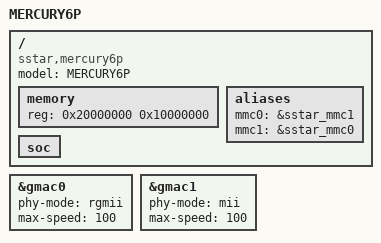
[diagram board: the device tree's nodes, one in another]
/*
* mercury6p.dts- Sigmastar
*
* Copyright (c) [2019~2020] SigmaStar Technology.
*
*
* This software is licensed under the terms of the GNU General Public
* License version 2, as published by the Free Software Foundation, and
* may be copied, distributed, and modified under those terms.
*
* This program is distributed in the hope that it will be useful,
* but WITHOUT ANY WARRANTY; without even the implied warranty of
* MERCHANTABILITY or FITNESS FOR A PARTICULAR PURPOSE.  See the
* GNU General Public License version 2 for more details.
*
*/


/dts-v1/;
/memreserve/ 0x20FC0000 0x00040000;
#include "mercury6p.dtsi"
#include "mercury6p-padmux.dtsi"

/ {
    model = "MERCURY6P";
    compatible = "sstar,mercury6p";
    #address-cells = <1>;
    #size-cells = <1>;

    /*
     * There are two methods to transmit DDR parameters to kernel:
     * 1) "LX_MEM=start_addr,len" parameters in bootargs, which has higher priority, will cover memory node parameters in dts;
     * 2) memory mode paramters in dts file, which has lower priority, only as spare parameter.
     */
    memory {
        device_type = "memory";
        #address-cells = <1>;
        #size-cells = <1>;
        reg = <0x20000000 0x10000000>;
    };

    // mmc aliases
    aliases {
        mmc0 = &sstar_mmc1; //FCIE
        mmc1 = &sstar_mmc0; //SDIO
    };

    soc {
        #include "mercury6p-clks-u-boot.dtsi"
    };
};

&gmac0 {
    phy-mode = "rgmii";
    max-speed = <100>;
    status = "okay";
};

&gmac1 {
    phy-mode = "mii";
    max-speed = <100>;
    status = "okay";
};
